AUTOSAR XML (schema 4-2-2)
package /IoHwAb_ADC
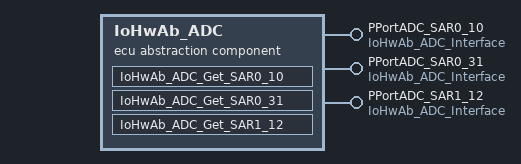
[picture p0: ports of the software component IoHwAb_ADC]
  ecu abstraction sw component type IoHwAb_ADC
    provide port PPortADC_SAR0_10: provided-interface=IoHwAb_ADC_Interface
    provide port PPortADC_SAR0_31: provided-interface=IoHwAb_ADC_Interface
    provide port PPortADC_SAR1_12: provided-interface=IoHwAb_ADC_Interface
    behavior IB_IoHwAb_ADC
      operation invoked event OIE_IoHwAb_ADC_Get_SAR0_31: start-on-event=IoHwAb_ADC_Get_SAR0_31, operation=PPortADC_SAR0_31.IoHwAb_ADC_Get
      operation invoked event OIE_IoHwAb_ADC_Get_SAR0_10: start-on-event=IoHwAb_ADC_Get_SAR0_10, operation=PPortADC_SAR0_10.IoHwAb_ADC_Get
      operation invoked event OIE_IoHwAb_ADC_Get_SAR1_12: start-on-event=IoHwAb_ADC_Get_SAR1_12, operation=PPortADC_SAR1_12.IoHwAb_ADC_Get
      runnable IoHwAb_ADC_Get_SAR0_10: symbol=IoHwAb_ADC_Get_SAR0_10_func
      runnable IoHwAb_ADC_Get_SAR0_31: symbol=IoHwAb_ADC_Get_SAR0_31_func
      runnable IoHwAb_ADC_Get_SAR1_12: symbol=IoHwAb_ADC_Get_SAR1_12_func
